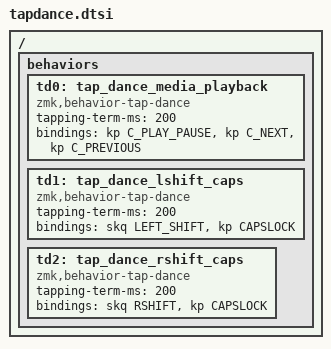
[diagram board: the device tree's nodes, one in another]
#include <behaviors.dtsi>
#include <dt-bindings/zmk/keys.h>

/ {
    behaviors {
        td0: tap_dance_media_playback {
            compatible = "zmk,behavior-tap-dance";
            #binding-cells = <0>;
            tapping-term-ms = <200>;
            bindings = <&kp C_PLAY_PAUSE>, <&kp C_NEXT>, <&kp C_PREVIOUS>;
        };
        td1: tap_dance_lshift_caps {
            compatible = "zmk,behavior-tap-dance";
            #binding-cells = <0>;
            tapping-term-ms = <200>;
            bindings = <&skq LEFT_SHIFT>, <&kp CAPSLOCK>;
        };
        td2: tap_dance_rshift_caps {
            compatible = "zmk,behavior-tap-dance";
            #binding-cells = <0>;
            tapping-term-ms = <200>;
            bindings = <&skq RSHIFT>, <&kp CAPSLOCK>;
        };
    };
};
